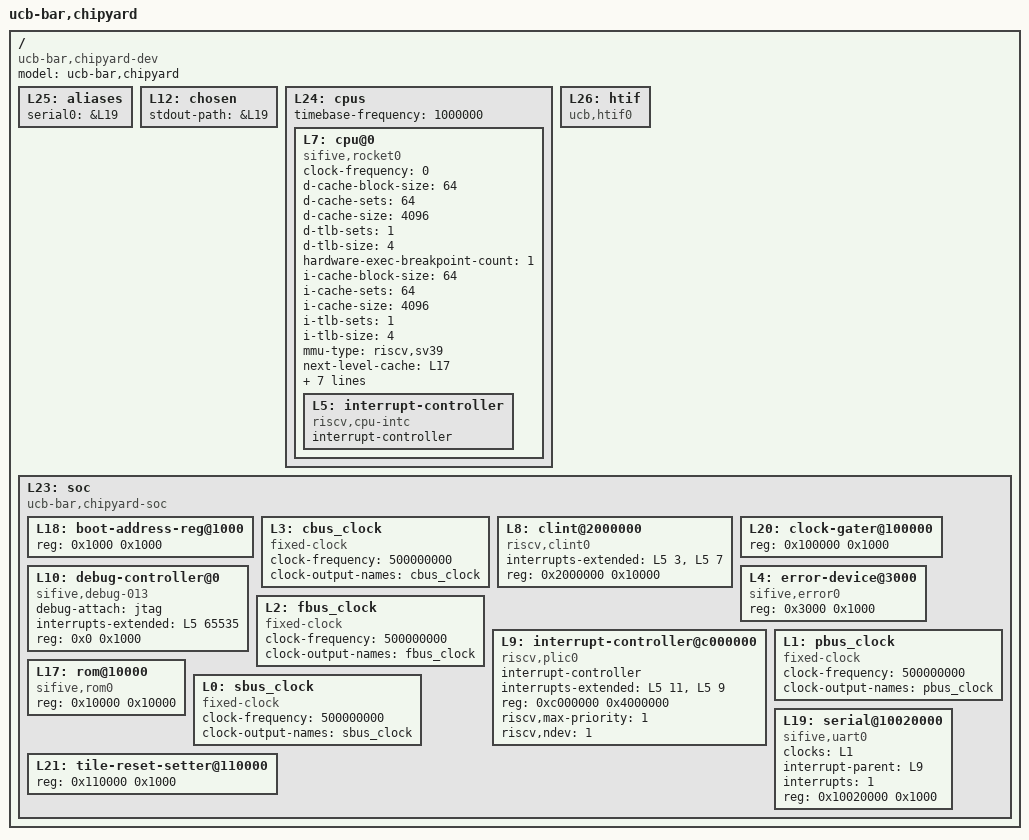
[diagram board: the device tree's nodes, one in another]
/dts-v1/;

/ {
	#address-cells = <1>;
	#size-cells = <1>;
	compatible = "ucb-bar,chipyard-dev";
	model = "ucb-bar,chipyard";
	L25: aliases {
		serial0 = &L19;
	};
	L12: chosen {
		stdout-path = &L19;
	};
	L24: cpus {
		#address-cells = <1>;
		#size-cells = <0>;
		timebase-frequency = <1000000>;
		L7: cpu@0 {
			clock-frequency = <0>;
			compatible = "sifive,rocket0", "riscv";
			d-cache-block-size = <64>;
			d-cache-sets = <64>;
			d-cache-size = <4096>;
			d-tlb-sets = <1>;
			d-tlb-size = <4>;
			device_type = "cpu";
			hardware-exec-breakpoint-count = <1>;
			i-cache-block-size = <64>;
			i-cache-sets = <64>;
			i-cache-size = <4096>;
			i-tlb-sets = <1>;
			i-tlb-size = <4>;
			mmu-type = "riscv,sv39";
			next-level-cache = <&L17>;
			reg = <0x0>;
			riscv,isa = "rv64imaczicsr_zifencei_zihpm_xrocket";
			riscv,pmpgranularity = <4>;
			riscv,pmpregions = <8>;
			status = "okay";
			timebase-frequency = <1000000>;
			tlb-split;
			L5: interrupt-controller {
				#interrupt-cells = <1>;
				compatible = "riscv,cpu-intc";
				interrupt-controller;
			};
		};
	};
	L26: htif {
		compatible = "ucb,htif0";
	};
	L23: soc {
		#address-cells = <1>;
		#size-cells = <1>;
		compatible = "ucb-bar,chipyard-soc", "simple-bus";
		ranges;
		L18: boot-address-reg@1000 {
			reg = <0x1000 0x1000>;
			reg-names = "control";
		};
		L3: cbus_clock {
			#clock-cells = <0>;
			clock-frequency = <500000000>;
			clock-output-names = "cbus_clock";
			compatible = "fixed-clock";
		};
		L8: clint@2000000 {
			compatible = "riscv,clint0";
			interrupts-extended = <&L5 3 &L5 7>;
			reg = <0x2000000 0x10000>;
			reg-names = "control";
		};
		L20: clock-gater@100000 {
			reg = <0x100000 0x1000>;
			reg-names = "control";
		};
		L10: debug-controller@0 {
			compatible = "sifive,debug-013", "riscv,debug-013";
			debug-attach = "jtag";
			interrupts-extended = <&L5 65535>;
			reg = <0x0 0x1000>;
			reg-names = "control";
		};
		L4: error-device@3000 {
			compatible = "sifive,error0";
			reg = <0x3000 0x1000>;
		};
		L2: fbus_clock {
			#clock-cells = <0>;
			clock-frequency = <500000000>;
			clock-output-names = "fbus_clock";
			compatible = "fixed-clock";
		};
		L9: interrupt-controller@c000000 {
			#interrupt-cells = <1>;
			compatible = "riscv,plic0";
			interrupt-controller;
			interrupts-extended = <&L5 11 &L5 9>;
			reg = <0xc000000 0x4000000>;
			reg-names = "control";
			riscv,max-priority = <1>;
			riscv,ndev = <1>;
		};
		L1: pbus_clock {
			#clock-cells = <0>;
			clock-frequency = <500000000>;
			clock-output-names = "pbus_clock";
			compatible = "fixed-clock";
		};
		L17: rom@10000 {
			compatible = "sifive,rom0";
			reg = <0x10000 0x10000>;
			reg-names = "mem";
		};
		L0: sbus_clock {
			#clock-cells = <0>;
			clock-frequency = <500000000>;
			clock-output-names = "sbus_clock";
			compatible = "fixed-clock";
		};
		L19: serial@10020000 {
			clocks = <&L1>;
			compatible = "sifive,uart0";
			interrupt-parent = <&L9>;
			interrupts = <1>;
			reg = <0x10020000 0x1000>;
			reg-names = "control";
		};
		L21: tile-reset-setter@110000 {
			reg = <0x110000 0x1000>;
			reg-names = "control";
		};
	};
};
